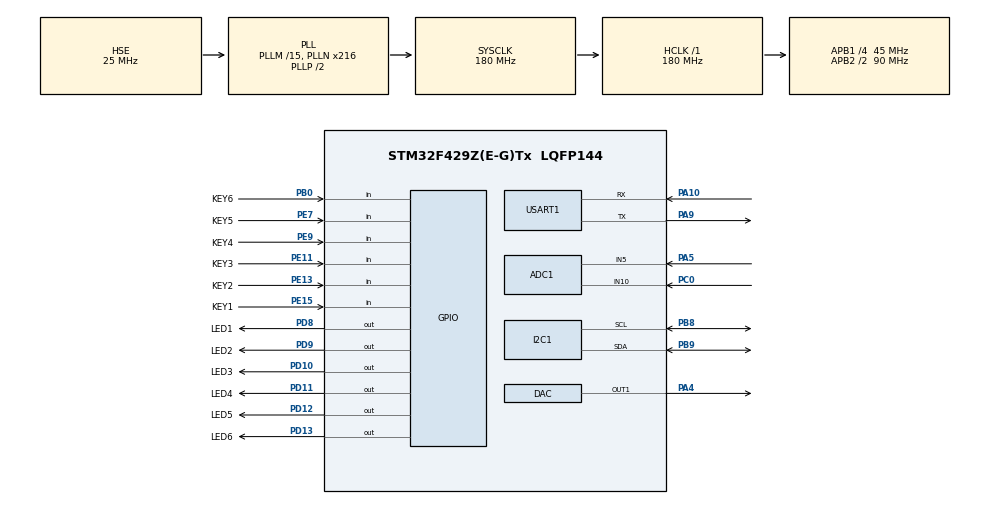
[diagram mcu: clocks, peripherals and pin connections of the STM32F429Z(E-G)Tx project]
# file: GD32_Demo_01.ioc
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ADC1.Channel-1\#ChannelRegularConversion=ADC_CHANNEL_10
ADC1.Channel-2\#ChannelRegularConversion=ADC_CHANNEL_5
ADC1.ContinuousConvMode=DISABLE
ADC1.DMAContinuousRequests=DISABLE
ADC1.ExternalTrigConv=ADC_EXTERNALTRIGCONV_T3_TRGO
ADC1.NbrOfConversion=2
ADC1.NbrOfConversionFlag=1
ADC1.Rank-1\#ChannelRegularConversion=1
ADC1.Rank-2\#ChannelRegularConversion=2
ADC1.SamplingTime-1\#ChannelRegularConversion=ADC_SAMPLETIME_15CYCLES
ADC1.SamplingTime-2\#ChannelRegularConversion=ADC_SAMPLETIME_3CYCLES
ADC1.ScanConvMode=ENABLE
ADC1.master=1
DAC.DAC_Trigger=DAC_TRIGGER_T6_TRGO
Dma.ADC1.1.Direction=DMA_PERIPH_TO_MEMORY
Dma.ADC1.1.FIFOMode=DMA_FIFOMODE_DISABLE
Dma.ADC1.1.Instance=DMA2_Stream0
Dma.ADC1.1.MemDataAlignment=DMA_MDATAALIGN_WORD
Dma.ADC1.1.MemInc=DMA_MINC_ENABLE
Dma.ADC1.1.Mode=DMA_NORMAL
Dma.ADC1.1.PeriphDataAlignment=DMA_PDATAALIGN_WORD
Dma.ADC1.1.PeriphInc=DMA_PINC_DISABLE
Dma.ADC1.1.Priority=DMA_PRIORITY_LOW
Dma.DAC1.2.Direction=DMA_MEMORY_TO_PERIPH
Dma.DAC1.2.FIFOMode=DMA_FIFOMODE_DISABLE
Dma.DAC1.2.Instance=DMA1_Stream5
Dma.DAC1.2.MemDataAlignment=DMA_MDATAALIGN_HALFWORD
Dma.DAC1.2.MemInc=DMA_MINC_ENABLE
Dma.DAC1.2.Mode=DMA_CIRCULAR
Dma.DAC1.2.PeriphDataAlignment=DMA_PDATAALIGN_HALFWORD
Dma.DAC1.2.PeriphInc=DMA_PINC_DISABLE
Dma.DAC1.2.Priority=DMA_PRIORITY_LOW
Dma.Request0=USART1_RX
Dma.Request1=ADC1
Dma.Request2=DAC1
Dma.USART1_RX.0.Direction=DMA_PERIPH_TO_MEMORY
Dma.USART1_RX.0.FIFOMode=DMA_FIFOMODE_DISABLE
Dma.USART1_RX.0.Instance=DMA2_Stream2
Dma.USART1_RX.0.MemDataAlignment=DMA_MDATAALIGN_BYTE
Dma.USART1_RX.0.MemInc=DMA_MINC_ENABLE
Dma.USART1_RX.0.Mode=DMA_CIRCULAR
Dma.USART1_RX.0.PeriphDataAlignment=DMA_PDATAALIGN_BYTE
Dma.USART1_RX.0.PeriphInc=DMA_PINC_DISABLE
Dma.USART1_RX.0.Priority=DMA_PRIORITY_LOW
I2C1.I2C_Mode=I2C_Fast
Mcu.Family=STM32F4
Mcu.Name=STM32F429Z(E-G)Tx
Mcu.Package=LQFP144
NVIC.ADC_IRQn=true\:0\:0\:false\:false\:true\:true\:true\:true
NVIC.DMA1_Stream5_IRQn=true\:0\:0\:false\:false\:true\:false\:true\:true
NVIC.DMA2_Stream0_IRQn=true\:0\:0\:false\:false\:true\:false\:true\:true
NVIC.DMA2_Stream2_IRQn=true\:0\:0\:false\:false\:true\:false\:true\:true
NVIC.PriorityGroup=NVIC_PRIORITYGROUP_4
NVIC.USART1_IRQn=true\:0\:0\:false\:false\:true\:true\:true\:true
PA10.Mode=Asynchronous
PA10.Signal=USART1_RX
PA13.Mode=Serial_Wire
PA13.Signal=SYS_JTMS-SWDIO
PA14.Mode=Serial_Wire
PA14.Signal=SYS_JTCK-SWCLK
PA4.Signal=COMP_DAC1_group
PA5.Signal=ADCx_IN5
PA9.Mode=Asynchronous
PA9.Signal=USART1_TX
PB0.GPIO_Label=KEY6
PB0.GPIO_PuPd=GPIO_PULLUP
PB0.Signal=GPIO_Input
PB8.Mode=I2C
PB8.Signal=I2C1_SCL
PB9.Mode=I2C
PB9.Signal=I2C1_SDA
PC0.Signal=ADCx_IN10
PC14/OSC32_IN.Mode=LSE-External-Oscillator
PC14/OSC32_IN.Signal=RCC_OSC32_IN
PC15/OSC32_OUT.Mode=LSE-External-Oscillator
PC15/OSC32_OUT.Signal=RCC_OSC32_OUT
PD10.GPIO_Label=LED3
PD10.Signal=GPIO_Output
PD11.GPIO_Label=LED4
PD11.Signal=GPIO_Output
PD12.GPIO_Label=LED5
PD12.Signal=GPIO_Output
PD13.GPIO_Label=LED6
PD13.Signal=GPIO_Output
PD8.GPIO_Label=LED1
PD8.Signal=GPIO_Output
PD9.GPIO_Label=LED2
PD9.Signal=GPIO_Output
PE11.GPIO_Label=KEY3
PE11.GPIO_PuPd=GPIO_PULLUP
PE11.Signal=GPIO_Input
PE13.GPIO_Label=KEY2
PE13.GPIO_PuPd=GPIO_PULLUP
PE13.Signal=GPIO_Input
PE15.GPIO_Label=KEY1
PE15.GPIO_PuPd=GPIO_PULLUP
PE15.Signal=GPIO_Input
PE7.GPIO_Label=KEY5
PE7.GPIO_PuPd=GPIO_PULLUP
PE7.Signal=GPIO_Input
PE9.GPIO_Label=KEY4
PE9.GPIO_PuPd=GPIO_PULLUP
PE9.Signal=GPIO_Input
PH0/OSC_IN.Mode=HSE-External-Oscillator
PH0/OSC_IN.Signal=RCC_OSC_IN
PH1/OSC_OUT.Mode=HSE-External-Oscillator
PH1/OSC_OUT.Signal=RCC_OSC_OUT
ProjectManager.HeapSize=0x400
ProjectManager.StackSize=0x800
ProjectManager.TargetToolchain=MDK-ARM V5.32
RCC.48MHZClocksFreq_Value=90000000
RCC.AHBFreq_Value=180000000
RCC.APB1CLKDivider=RCC_HCLK_DIV4
RCC.APB1Freq_Value=45000000
RCC.APB1TimFreq_Value=90000000
RCC.APB2CLKDivider=RCC_HCLK_DIV2
RCC.APB2Freq_Value=90000000
RCC.APB2TimFreq_Value=180000000
RCC.CortexFreq_Value=180000000
RCC.HCLKFreq_Value=180000000
RCC.HSE_VALUE=25000000
RCC.HSI_VALUE=16000000
RCC.PLLM=15
RCC.PLLN=216
RCC.PLLSourceVirtual=RCC_PLLSOURCE_HSE
RCC.SYSCLKFreq_VALUE=180000000
RCC.SYSCLKSource=RCC_SYSCLKSOURCE_PLLCLK
RCC.VCOOutputFreq_Value=360000000
SH.ADCx_IN10.0=ADC1_IN10,IN10
SH.ADCx_IN5.0=ADC1_IN5,IN5
SH.COMP_DAC1_group.0=DAC_OUT1,DAC_OUT1
TIM3.AutoReloadPreload=TIM_AUTORELOAD_PRELOAD_ENABLE
TIM3.Period=100-1
TIM3.Prescaler=90-1
TIM3.TIM_MasterOutputTrigger=TIM_TRGO_UPDATE
TIM6.AutoReloadPreload=TIM_AUTORELOAD_PRELOAD_ENABLE
TIM6.Period=100-1
TIM6.Prescaler=90 -1
TIM6.TIM_MasterOutputTrigger=TIM_TRGO_UPDATE
USART1.VirtualMode=VM_ASYNC
VP_TIM3_VS_ClockSourceINT.Mode=Internal
VP_TIM6_VS_ClockSourceINT.Mode=Enable_Timer
board=custom

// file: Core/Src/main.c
/* USER CODE BEGIN Header */
/**
  ******************************************************************************
  * @file           : main.c
  * @brief          : Main program body
  ******************************************************************************
  * @attention
  *
  * Copyright (c) 2025 STMicroelectronics.
  * All rights reserved.
  *
  * This software is licensed under terms that can be found in the LICENSE file
  * in the root directory of this software component.
  * If no LICENSE file comes with this software, it is provided AS-IS.
  *
  ******************************************************************************
  */
/* USER CODE END Header */
#include "main.h"
#include "adc.h"
#include "dac.h"
#include "dma.h"
#include "i2c.h"
#include "tim.h"
#include "usart.h"
#include "gpio.h"

/* USER CODE BEGIN Includes */
#include "scheduler.h"
u8g2_t u8g2;//实例化一个u8g2
/* USER CODE END Includes */

void SystemClock_Config(void);

int main(void)
{

  /* MCU Configuration--------------------------------------------------------*/

  /* Reset of all peripherals, Initializes the Flash interface and the Systick. */
  HAL_Init();

  /* Configure the system clock */
  SystemClock_Config();

  /* Initialize all configured peripherals */
  MX_GPIO_Init();
  MX_DMA_Init();
  MX_USART1_UART_Init();
  MX_ADC1_Init();
  MX_TIM3_Init();
  MX_DAC_Init();
  MX_TIM6_Init();
  MX_I2C1_Init();
  /* USER CODE BEGIN 2 */

	// u8g2 初始化
  // 1. Setup: 这是最关键的一步，它配置了 u8g2 实例。
  //    - 选择与硬件匹配的 setup 函数 (SSD1306, I2C, 128x32, Full Buffer)。
  //    - &u8g2: 指向要配置的 u8g2 结构体实例的指针。
  //    - U8G2_R0: 旋转设置。U8G2_R0=0°, U8G2_R1=90°, U8G2_R2=180°, U8G2_R3=270°。
  //    - u8x8_byte_hw_i2c: 指向你的硬件 I2C 字节传输回调函数的指针。
  //    - u8g2_gpio_and_delay_stm32: 指向你的 GPIO 和延时回调函数的指针。
  u8g2_Setup_ssd1306_i2c_128x32_univision_f(&u8g2, U8G2_R0, u8x8_byte_hw_i2c, u8g2_gpio_and_delay_stm32);
  //    - &u8g2: u8g2 结构体指针
  //    - U8G2_R0: 旋转设置 (0度)
  // 2. Init Display: 发送初始化序列到 OLED
  u8g2_InitDisplay(&u8g2);

  // 3. Set Power Save: 唤醒屏幕。
  //    - 参数 0 表示关闭省电模式 (屏幕亮起)。
  //    - 参数 1 表示进入省电模式 (屏幕熄灭)。
  u8g2_SetPowerSave(&u8g2, 0);

  // (可选) 4. Clear Display: 清空屏幕物理显存。
  //    - 这个函数会立即发送清屏命令到设备。
  //    - 注意与 `u8g2_ClearBuffer` 的区别，后者仅清空内存中的缓冲区。
  // u8g2_ClearDisplay(&u8g2);

	uart_init();//串口初始化
  adc_tim_dma_init();//ADC_DMA初始化 首次手动启用DMA
	dac_sin_init();//dac 初始化函数
	my_ebtn_init();
//	OLED_Init();
	scheduler_init();
  /* USER CODE END 2 */

  /* Infinite loop */
  while (1)
  {

    /* USER CODE BEGIN 3 */
		scheduler_run();

  }
  /* USER CODE END 3 */
}

void SystemClock_Config(void)
{
  RCC_OscInitTypeDef RCC_OscInitStruct = {0};
  RCC_ClkInitTypeDef RCC_ClkInitStruct = {0};

  /** Configure the main internal regulator output voltage
  */
  __HAL_RCC_PWR_CLK_ENABLE();
  __HAL_PWR_VOLTAGESCALING_CONFIG(PWR_REGULATOR_VOLTAGE_SCALE1);

  /** Initializes the RCC Oscillators according to the specified parameters
  * in the RCC_OscInitTypeDef structure.
  */
  RCC_OscInitStruct.OscillatorType = RCC_OSCILLATORTYPE_HSE;
  RCC_OscInitStruct.HSEState = RCC_HSE_ON;
  RCC_OscInitStruct.PLL.PLLState = RCC_PLL_ON;
  RCC_OscInitStruct.PLL.PLLSource = RCC_PLLSOURCE_HSE;
  RCC_OscInitStruct.PLL.PLLM = 15;
  RCC_OscInitStruct.PLL.PLLN = 216;
  RCC_OscInitStruct.PLL.PLLP = RCC_PLLP_DIV2;
  RCC_OscInitStruct.PLL.PLLQ = 4;
  if (HAL_RCC_OscConfig(&RCC_OscInitStruct) != HAL_OK)
  {
    Error_Handler();
  }

  /** Activate the Over-Drive mode
  */
  if (HAL_PWREx_EnableOverDrive() != HAL_OK)
  {
    Error_Handler();
  }

  /** Initializes the CPU, AHB and APB buses clocks
  */
  RCC_ClkInitStruct.ClockType = RCC_CLOCKTYPE_HCLK|RCC_CLOCKTYPE_SYSCLK
                              |RCC_CLOCKTYPE_PCLK1|RCC_CLOCKTYPE_PCLK2;
  RCC_ClkInitStruct.SYSCLKSource = RCC_SYSCLKSOURCE_PLLCLK;
  RCC_ClkInitStruct.AHBCLKDivider = RCC_SYSCLK_DIV1;
  RCC_ClkInitStruct.APB1CLKDivider = RCC_HCLK_DIV4;
  RCC_ClkInitStruct.APB2CLKDivider = RCC_HCLK_DIV2;

  if (HAL_RCC_ClockConfig(&RCC_ClkInitStruct, FLASH_LATENCY_5) != HAL_OK)
  {
    Error_Handler();
  }
}

void Error_Handler(void)
{
  __disable_irq();
  while (1)
  {
  }
}
